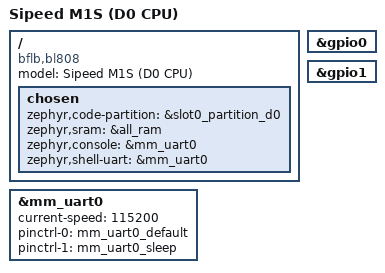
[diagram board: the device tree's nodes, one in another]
/*
 * Copyright The Zephyr Project Contributors
 *
 * SPDX-License-Identifier: Apache-2.0
 */

#include <bflb/bl808-d0.dtsi>
#include "m1s_common.dtsi"

/ {
	model = "Sipeed M1S (D0 CPU)";
	compatible = "bflb,bl808";

	chosen {
		zephyr,code-partition = &slot0_partition_d0;
		zephyr,sram = &all_ram;
		zephyr,console = &mm_uart0;
		zephyr,shell-uart = &mm_uart0;
	};
};

&mm_uart0 {
	status = "okay";
	current-speed = <115200>;

	pinctrl-0 = <&mm_uart0_default>;
	pinctrl-1 = <&mm_uart0_sleep>;
	pinctrl-names = "default", "sleep";
};

&gpio0 {
	status = "okay";
};

&gpio1 {
	status = "okay";
};
